# ET6801 register map
Vendor: ETMCU Inc.; File version: v0.0.1
CPU: CM7 r2p1, little endian, MPU, FPU, I-cache, D-cache, ITCM, DTCM, 4 interrupt priority bits
Registers are 32-bit, read-write, reset 0x0 unless marked. A register's access mark holds for its fields unless they carry their own. Offsets are from the block's base; [hi:lo] are bit positions; lines under a group give offsets from that group; {n}, {i} and the like mark numbered series.

## AHBDMA0 (part 1 of 2) — Provide an overview of the purpose and functionality of the peripheral: hdmac_cfg
Base 0x40200000
Same registers: AHBDMA1 0x40201000
{0x0+0x58*i} CHANNELX_CONFIG_CH{i} group (i=0..7)
  0x00 SARX
    [31:0] SAR — Current Source Address of DMA transfer. Updated after each source transfer. The SINC field in the CTLx register determines whether the address increments, decrements, or is left unchanged on every source transfer through the block transfer.Exists: AlwaysVolatile: true
  0x08 DARX
    [31:0] DAR — Current Destination address of DMA transfer. Updated after each destination transfer. The DINC field in the CTLx register determines whether the address increments, decrements, or is left unchanged on every destination transfer throughout the block transfer.
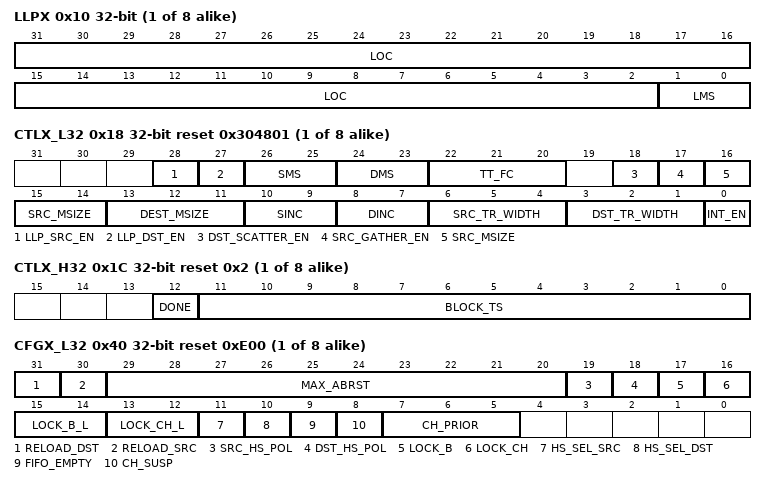
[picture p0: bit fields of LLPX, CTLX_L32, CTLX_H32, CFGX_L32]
  0x10 LLPX
    [31:2] LOC — Starting Address In Memory of next LLI if block chaining is enabled. Note that the two LSBs of the starting address are not stored because the address is assumed to be aligned to a 32-bit boundary. LLI accesses are always 32-bit accesses (Hsize=2) aligned to 32-bit boundaries and cannot be changed or programmed to anything other than 32-bit.
    [1:0] LMS — List Master Select. Identifies the AHB layer/interface where the memory device that stores the next linked list item resides. Values: 0x0 (LIST_MASTER_SELECT_1): The memory device stores the next linked list item on AHB master 1
  0x18 CTLX_L32 reset 0x304801 (reset mask 0xFFFFEFF8)
    [28] LLP_SRC_EN — Block chaining is enabled on the source side only if the LLP_SRC_EN field is high and LLPx.LOC is non-zero. For more information, see "Block Chaining using Linked Lists".Values: 0x0 (LLP_SRC_DISABLE): Block chaining using Linked List is disabled on the Source side0x1 (LLP_SRC_ENABLE): Block chaining using Linked List is enabled on the Source side
    [27] LLP_DST_EN — Block chaining is enabled on the destination side only if LLP_DST_EN field is high and LLPx.LOC is non-zero. For more information, see "Block Chaining using Linked Lists".Values: 0x0 (LLP_DST_DISABLE): Block chaining using Linked List is disabled on the Destination side0x1 (LLP_DST_ENABLE): Block chaining using Linked List is enabled on the Destination side
    [26:25] SMS — Source Master Select. Identifies the Master Interface layer where the source device (peripheral or memory) resides. Values: 0x0 (SMS_0): Source device (peripheral or memory) is accessed from AHB master 1
    [24:23] DMS — Destination Master Select. Identifies the Master Interface layer where the destination device (peripheral or memory) resides. Values: 0x0 (DMS_0): Destination device (peripheral or memory) is accessed from AHB master 1
    [22:20] TT_FC — Transfer Type and Flow Control.Values: 0x0 (TT_FC_0): Transfer type is Memory to Memory and Flow Controller is AHB DMAC0x1 (TT_FC_1): Transfer type is Memory to Peripheral and Flow Controller is AHB DMAC0x2 (TT_FC_2): Transfer type is Peripheral to Memory and Flow Controller is AHB DMAC0x3 (TT_FC_3): Transfer type is Peripheral to Peripheral and Flow Controller is AHB DMAC
    [18] DST_SCATTER_EN — Destination scatter enable. Scatter on the destination side is applicable only when the CTLx.DINC bit indicates an incrementing or decrementing address control.Values: 0x0 (DST_SCATTER_DISABLE): Destination Scatter is disabled0x1 (DST_SCATTER_ENABLE): Destination Scatter is enabled
    [17] SRC_GATHER_EN — Source gather enable. Gather on the source side is applicable only when the CTLx.SINC bit indicates an incrementing or decrementing address control.Values: 0x0 (SRC_GATHER_DISABLE): Source gather is disabled0x1 (SRC_GATHER_ENABLE): Source gather is enabled
    [16:14] SRC_MSIZE — Source Burst Transaction Length. Values: 0x0 (SRC_MSIZE_0): Number of data items to be transferred is 10x1 (SRC_MSIZE_1): Number of data items to be transferred is 40x2 (SRC_MSIZE_2): Number of data items to be transferred is 80x3 (SRC_MSIZE_3): Number of data items to be transferred is 160x4 (SRC_MSIZE_4): Number of data items to be transferred is 320x5 (SRC_MSIZE_5): Number of data items to be transferred is 640x6 (SRC_MSIZE_6): Number of data items to be transferred is 1280x7 (SRC_MSIZE_7): Number of data items to be transferred is 256
    [13:11] DEST_MSIZE — Destination Burst Transaction Length. NOTE: This value is not related to the AHB bus master HBURST bus.Values: 0x0 (DEST_MSIZE_0): Number of data items to be transferred is 10x1 (DEST_MSIZE_1): Number of data items to be transferred is 40x2 (DEST_MSIZE_2): Number of data items to be transferred is 80x3 (DEST_MSIZE_3): Number of data items to be transferred is 160x4 (DEST_MSIZE_4): Number of data items to be transferred is 320x5 (DEST_MSIZE_5): Number of data items to be transferred is 640x6 (DEST_MSIZE_6): Number of data items to be transferred is 1280x7 (DEST_MSIZE_7): Number of data items to be transferred is 256
    [10:9] SINC — Source Address Increment. Indicates whether to increment or decrement the source address on every source transfer. If the device is fetching data from a source peripheral FIFO with a fixed address, then set this field to "No change".Values: 0x0 (SINC_0): Increments the source address0x1 (SINC_1): Decrements the source address0x2 (SINC_2): No change in the source address0x3 (SINC_3): No change in the source address
    [8:7] DINC — Destination Address Increment. Indicates whether to increment or decrement the destination address on every destination transfer. If your device is writing data to a destination peripheral FIFO with a fixed address, then set this field to \"No Change\".Values: 0x0 (DINC_0): Increments the destination address0x1 (DINC_1): Decrements the destination address0x2 (DINC_2): No change in the destination address0x3 (DINC_3): No change in the destination address
    [6:4] SRC_TR_WIDTH — Source Transfer Width. Mapped to AHB bus hsize. Values: 0x0 (SRC_TR_WIDTH_0): Source transfer width is 8 bits0x1 (SRC_TR_WIDTH_1): Source transfer width is 16 bits0x2 (SRC_TR_WIDTH_2): Source transfer width is 32 bits0x3 (SRC_TR_WIDTH_3): Source transfer width is 64 bits0x4 (SRC_TR_WIDTH_4): Source transfer width is 128 bits0x5 (SRC_TR_WIDTH_5): Source transfer width is 256 bits0x6 (SRC_TR_WIDTH_6): Source transfer width is 256 bits0x7 (SRC_TR_WIDTH_7): Source transfer width is 256 bits
    [3:1] DST_TR_WIDTH — Destination Transfer Width. Mapped to AHB bus hsize. Values: 0x0 (DST_TR_WIDTH_0): Destination transfer width is 8 bits0x1 (DST_TR_WIDTH_1): Destination transfer width is 16 bits0x2 (DST_TR_WIDTH_2): Destination transfer width is 32 bits0x3 (DST_TR_WIDTH_3): Destination transfer width is 64 bits0x4 (DST_TR_WIDTH_4): Destination transfer width is 128 bits0x5 (DST_TR_WIDTH_5): Destination transfer width is 256 bits0x6 (DST_TR_WIDTH_6): Destination transfer width is 256 bits0x7 (DST_TR_WIDTH_7): Destination transfer width is 256 bits
    [0] INT_EN — Interrupt Enable Bit. If set, then all interrupt-generating sources are enabled. Functions as a global mask bit for all interrupts for the channel; raw* interrupt registers still assert if CTLx.INT_EN=0.Values: 0x0 (INTERRUPT_DISABLE): Interrupt is disabled0x1 (INTERRUPT_ENABLE): Interrupt is enabled
  0x1C CTLX_H32 reset 0x2 (reset mask 0xFFF80000)
    [12] DONE — Done bit.Values: 0x0 (DISABLED): DONE bit is deasserted at the end of block transfer0x1 (ENABLED): SET the DONE bit at the end of block transfer
    [11:0] BLOCK_TS — Block Transfer Size.
  0x20 SSTATX
    [31:0] SSTAT — Source status information retrieved by hardware from the address pointed to by the contents of the STATARx register
  0x28 DSTATX
    [31:0] DSTAT — Destination status information retrieved by hardware from the address pointed to by the contents of DSTATARx register.
  0x30 SSTATARX
    [31:0] SSTATAR — Pointer from where hardware can fetch the source status information, which is registered in the SSTATx register and written out to the SSTATx register location of the LLI before the start of the next block.
  0x38 DSTATARX
    [31:0] DSTATAR — Pointer from where hardware can fetch the destination status information, which is registered in the DSTATx register and written out to the DSTATx register location of the LLI before the start of the next block.
  0x40 CFGX_L32 reset 0xE00 (reset mask 0x7FFFFFF)
    [31] RELOAD_DST — Automatic Destination Reload. Values: 0x0 (DISABLE): Destination Reload Disabled.0x1 (ENABLE): Destination Reload Enabled
    [30] RELOAD_SRC — Automatic Source Reload. Values: 0x0 (DISABLE): Source Reload Disabled0x1 (ENABLE): Source Reload Enabled
    [29:20] MAX_ABRST — Maximum AMBA Burst Length.
    [19] SRC_HS_POL — Source Handshaking Interface Polarity.Values: 0x0 (ACTIVE_HIGH): Source Handshaking Interface Polarity is Active high0x1 (ACTIVE_LOW): Source Handshaking Interface Polarity is Active low
    [18] DST_HS_POL — Destination Handshaking Interface Polarity.Values: 0x0 (ACTIVE_HIGH): Destination Handshaking Interface Polarity is Active high0x1 (ACTIVE_LOW): Destination Handshaking Interface Polarity is Active low
    [17] LOCK_B — Bus Lock Bit. When active, the AHB bus master signal hlock is asserted for the duration specified in CFGx.LOCK_B_L. Values: 0x0 (DISABLED): Bus lock bit is not enabled0x1 (ENABLED): Bus lock bit is enabledExists: DMAH_CHx_LOCK_EN
    [16] LOCK_CH — Channel Lock Bit. When the channel is granted control of the master bus interface and if the CFGx.LOCK_CH bit is asserted, then no other channels are granted control of the master bus interface for the duration specified in CFGx.LOCK_CH_L.Values: 0x0 (DISABLED): Channel lock bit is not enabled0x1 (ENABLED): Channel lock bit is enabled
    [15:14] LOCK_B_L — Bus lock level. Indicates the duration over which CFGx.LOCK_B bit applies. Values: 0x0 (LOCK_B_L_0): Over complete DMA transfer0x1 (LOCK_B_L_1): Over complete DMA block transfer0x2 (LOCK_B_L_2): Over complete DMA transaction0x3 (LOCK_B_L_3): Over complete DMA transaction
    [13:12] LOCK_CH_L — Channel Local Level. Indicates the duration over which CFGx.LOCK_CH applies. Values: 0x0 (LOCK_CH_L_0): Over complete DMA transfer0x1 (LOCK_CH_L_1): Over complete DMA block transfer0x2 (LOCK_CH_L_2): Over complete DMA transaction0x3 (LOCK_CH_L_3): Over complete DMA transaction
    [11] HS_SEL_SRC — Source Software or Hardware Handshaking Select. This register selects which of the handshaking interfaces - hardware or software - is active for source requests on this channel. If the source peripheral is memory, then this bit is ignored.Values: 0x0 (HARDWARE_HS): Hardware handshaking interface. Software initiated transaction requests are ignored.0x1 (SOFTWARE_HS): Software handshaking interface. Hardware initiated transaction requests are ignored.
    [10] HS_SEL_DST — Destination Software or Hardware Handshaking Select. This register selects which of the handshaking interfaces - hardware or software - is active for destination requests on this channel. If the destination peripheral is memory, then this bit is ignored.Values: 0x0 (HARDWARE_HS): Hardware handshaking interface. Software initiated transaction requests are ignored.0x1 (SOFTWARE_HS): Software handshaking interface. Hardware initiated transaction requests are ignored.
    [9] FIFO_EMPTY ro — Channel FIFO status. Indicates if there is data left in the channel FIFO. Can be used in conjunction with CFGx.CH_SUSP to cleanly disable a channel. For more information, refer to "Disabling a Channel Prior to Transfer Completion".Values: 0x0 (NOT_EMPTY): Channel FIFO is not empty0x1 (EMPTY): Channel FIFO is empty
    [8] CH_SUSP — Channel Suspend. Suspends all DMA data transfers from the source until this bit is cleared. There is no guarantee that the current transaction will complete. Can also be used in conjunction with CFGx.FIFO_EMPTY to cleanly disable a channel without losing any data.0x0 (NOT_SUSPENDED): DMA transfer from the source is not suspended0x1 (SUSPENDED): Suspend DMA transfer from the source
    [7:5] CH_PRIOR — Channel Priority. A priority of 7 is the highest priority, and 0 is the lowest. This field must be programmed within the range 0 to DMAH_NUM_CHANNELS-1. A programmed value outside this range will cause erroneous behavior.DMA CH0默认值为0，DMA CH1 默认值为1，依次类推，DMA CH7 默认值为7Values: 0x0 (CH_PRIOR_0): Channel priority is 00x1 (CH_PRIOR_1): Channel priority is 10x2 (CH_PRIOR_2): Channel priority is 20x3 (CH_PRIOR_3): Channel priority is 30x4 (CH_PRIOR_4): Channel priority is 40x5 (CH_PRIOR_5): Channel priority is 50x6 (CH_PRIOR_6): Channel priority is 60x7 (CH_PRIOR_7): Channel priority is 7
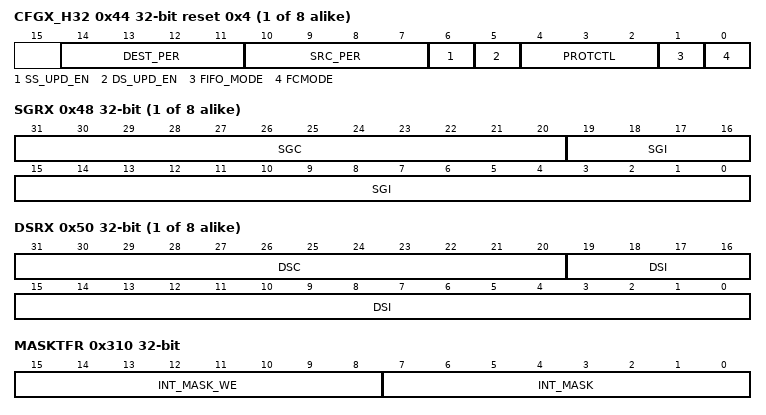
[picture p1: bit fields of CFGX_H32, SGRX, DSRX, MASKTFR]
  0x44 CFGX_H32 reset 0x4 (reset mask 0xFFFE0000)
    [14:11] DEST_PER — Destination hardware interface.Assigns a hardware handshaking interface (0 : 15) to the source of channel xThe channel can then communicate with the destination peripheral connected to that interface through the assigned hardware handshaking interface.
    [10:7] SRC_PER — Source Hardware Interface..Assigns a hardware handshaking interface (0 : 15) to the source of channel x
    [6] SS_UPD_EN — Source Status Update Enable. Source status information is fetched only from the location pointed to by the SSTATARx register, stored in the SSTATx register and written out to the SSTATx location of the LLI, if SS_UPD_EN is high.Values: 0x0 (DISABLED): Source Status Update is disabled.0x1 (ENABLED): Source Status Update is enabled.
    [5] DS_UPD_EN — Destination Status Update Enable. Destination status information is fetched only from the location pointed to by the DSTATARx register, stored in the DSTATx register and written out to the DSTATx location of the LLI, if DS_UPD_EN is high.Values: 0x0 (DISABLED): Destination Status Update is disabled0x1 (ENABLED): Destination Status Update is enabled
    [4:2] PROTCTL — Protection Control bits used to drive the AHB HPROT[3:1] bus. The AMBA Specification recommends that the default of HPROT indicates a non-cached, non-buffered, privileged data access. The reset value is used to indicate such an access.HPROT[0] is tied high because all transfers are data accesses, as there are no opcode fetches.There is a one-to-one mapping of these register bits to the HPROT[3:1] master interface signals.Mapping of HPROT bus is as follows:1'b1 to HPROT[0]CFGx.PROTCTL[1] to HPROT[1]CFGx.PROTCTL[2] to HPROT[2]CFGx.PROTCTL[3] to HPROT[3]Values: 0x0 (PROT_0): Drive the AHB HPROT[0] bus.The AMBA Specification recommends that the default value of HPROT indicates a non-cached, non-buffered, privileged data access0x1 (PROT_1): Drive the AHB HPROT[1] bus.The AMBA Specification recommends that the default value of HPROT indicates a non-cached, non-buffered, privileged data access0x2 (PROT_2): Drive the AHB HPROT[2] bus.The AMBA Specification recommends that the default value of HPROT indicates a non-cached, non-buffered, privileged data access0x3 (PROT_3): Drive the AHB HPROT[3] bus.The AMBA Specification recommends that the default value of HPROT indicates a non-cached, non-buffered, privileged data access0x4 (PROT_4): Drive the AHB HPROT[4] bus.The AMBA Specification recommends that the default value of HPROT indicates a non-cached, non-buffered, privileged data access0x5 (PROT_5): Drive the AHB HPROT[5] bus.The AMBA Specification recommends that the default value of HPROT indicates a non-cached, non-buffered, privileged data access0x5 (PROT_6): Drive the AHB HPROT[6] bus.The AMBA Specification recommends that the default value of HPROT indicates a non-cached, non-buffered, privileged data access0x7 (PROT_7): Drive the AHB HPROT[7] bus.The AMBA Specification recommends that the default value of HPROT indicates a non-cached, non-buffered, privileged data access
    [1] FIFO_MODE — FIFO Mode Select. Determines how much space or data needs to be available in the FIFO before a burst transaction request is serviced.Values: 0x0 (FIFO_MODE_0): Space/data available for single AHB transfer of the specified transfer width0x1 (FIFO_MODE_1): Data available is greater than or equal to half the FIFO depth for destination transfers and space available is greater than half the fifo depth for source transfers. The exceptions are at the end of a burst transaction request or at the end of a block transfer.
    [0] FCMODE — Flow Control Mode. Determines when source transaction requests are serviced when the Destination Peripheral is the flow controller.Values: 0x0 (FCMODE_0): Source transaction requests are serviced when they occur. Data pre-fetching is enabled0x1 (FCMODE_1): Source transaction requests are not serviced until a destination transaction request occurs. In this mode, the amount of data transferred from the source is limited so that it is guaranteed to be transferred to the destination prior to block termination by the destination. Data pre-fetching is disabled.
  0x48 SGRX
    [31:20] SGC — Source Gather Count. Source contiguous transfer count between successive gather boundaries.
    [19:0] SGI — Source Gather Interval.
  0x50 DSRX
    [31:20] DSC — Destination Scatter Count. Destination contiguous transfer count between successive scatter boundaries.
    [19:0] DSI — Destination Scatter Interval.
0x2C0 RAWTFR (reset mask 0xFF000000)
  [7:0] RAW — Raw Status for IntTfr InterruptValues: 0x0 (INACTIVE): Inactive Raw Interrupt Status0x1 (ACTIVE): Active Raw Interrupt Status
0x2C8 RAWBLOCK (reset mask 0xFF000000)
  [7:0] RAW — Raw Status for IntBlock InterruptValues: 0x0 (INACTIVE): Inactive Raw Interrupt Status0x1 (ACTIVE): Active Raw Interrupt Status
0x2D0 RAWSRCTRAN (reset mask 0xFF000000)
  [7:0] RAW — Raw Status for IntSrcTran InterruptValues: 0x0 (INACTIVE): Inactive Raw Interrupt Status0x1 (ACTIVE): Active Raw Interrupt Status
0x2D8 RAWDSTTRAN (reset mask 0xFF000000)
  [7:0] RAW — Raw Status for IntDstTran InterruptValues: 0x0 (INACTIVE): Inactive Raw Interrupt Status0x1 (ACTIVE): Active Raw Interrupt Status
0x2E0 RAWERR (reset mask 0xFF000000)
  [7:0] RAW — Raw Status for IntErr InterruptValues: 0x0 (INACTIVE): Inactive Raw Interrupt Status0x1 (ACTIVE): Active Raw Interrupt Status
0x2E8 STATUSTFR ro (reset mask 0xFF000000)
  [7:0] STATUS — Status for IntTfr InterruptValues: 0x0 (INACTIVE): Inactive Interrupt Status0x1 (ACTIVE): Active Interrupt Status
0x2F0 STATUSBLOCK ro (reset mask 0xFF000000)
  [7:0] STATUS — Status for IntBlock InterruptValues: 0x0 (INACTIVE): Inactive Interrupt Status0x1 (ACTIVE): Active Interrupt Status
0x2F8 STATUSSRCTRAN ro (reset mask 0xFF000000)
  [7:0] STATUS — Status for IntSrcTran InterruptValues: 0x0 (INACTIVE): Inactive Interrupt Status0x1 (ACTIVE): Active Interrupt Status
0x300 STATUSDSTTRAN ro (reset mask 0xFF000000)
  [7:0] STATUS — Status for IntDstTran InterruptValues: 0x0 (INACTIVE): Inactive Interrupt Status0x1 (ACTIVE): Active Interrupt Status
0x308 STATUSERR ro (reset mask 0xFF000000)
  [7:0] STATUS — Status for IntErr InterruptValues: 0x0 (INACTIVE): Inactive Interrupt Status0x1 (ACTIVE): Active Interrupt Status
0x310 MASKTFR (reset mask 0xFFFF0000)
  [15:8] INT_MASK_WE — Interrupt Mask Write EnableValues: 0x0 (DISABLED): Interrupt mask write disable0x1 (ENABLED): Interrupt mask write enable
  [7:0] INT_MASK — Mask for IntTfr InterruptValues: 0x0 (MASK): Mask the interrupts0x1 (UNMASK): Unmask the interrupts
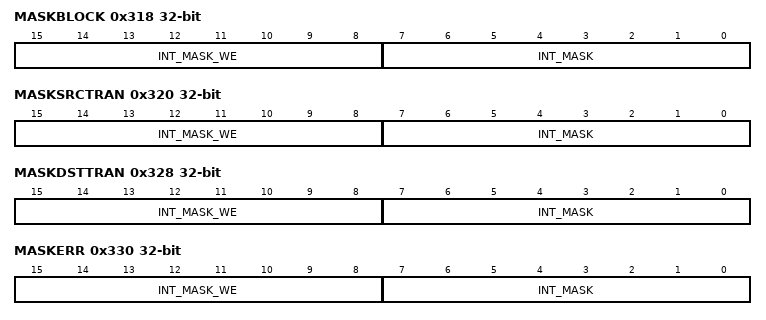
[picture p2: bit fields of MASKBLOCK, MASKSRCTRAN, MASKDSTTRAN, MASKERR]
0x318 MASKBLOCK (reset mask 0xFFFF0000)
  [15:8] INT_MASK_WE — Interrupt Mask Write EnableValues: 0x0 (DISABLED): Interrupt mask write disable0x1 (ENABLED): Interrupt mask write enable
  [7:0] INT_MASK — Mask for IntBlock InterruptValues: 0x0 (MASK): Mask the interrupts0x1 (UNMASK): Unmask the interrupts
0x320 MASKSRCTRAN (reset mask 0xFFFF0000)
  [15:8] INT_MASK_WE — Interrupt Mask Write EnableValues: 0x0 (DISABLED): Interrupt mask write disable0x1 (ENABLED): Interrupt mask write enable
  [7:0] INT_MASK — Mask for IntSrcTran InterruptValues: 0x0 (MASK): Mask the interrupts0x1 (UNMASK): Unmask the interrupts
0x328 MASKDSTTRAN (reset mask 0xFFFF0000)
  [15:8] INT_MASK_WE — Interrupt Mask Write EnableValues: 0x0 (DISABLED): Interrupt mask write disable0x1 (ENABLED): Interrupt mask write enable
  [7:0] INT_MASK — Mask for IntDstTran InterruptValues: 0x0 (MASK): Mask the interrupts0x1 (UNMASK): Unmask the interrupts
0x330 MASKERR (reset mask 0xFFFF0000)
  [15:8] INT_MASK_WE — Interrupt Mask Write EnableValues: 0x0 (DISABLED): Interrupt mask write disable0x1 (ENABLED): Interrupt mask write enable
  [7:0] INT_MASK — Mask for IntErr InterruptValues: 0x0 (MASK): Mask the interrupts0x1 (UNMASK): Unmask the interrupts
0x338 CLEARTFR (reset mask 0xFF000000)
  [7:0] CLEAR — Clear for IntTfr InterruptValues: 0x0 (NOT_CLEAR): No effect0x1 (CLEAR): Clears interrupts
0x340 CLEARBLOCK (reset mask 0xFF000000)
  [7:0] CLEAR — Clear for IntBlock InterruptValues: 0x0 (NOT_CLEAR): No effect0x1 (CLEAR): Clears interrupts
0x348 CLEARSRCTRAN (reset mask 0xFF000000)
  [7:0] CLEAR — Clear for IntSrcTran InterruptValues: 0x0 (NOT_CLEAR): No effect0x1 (CLEAR): Clears interrupts
0x350 CLEARDSTTRAN (reset mask 0xFF000000)
  [7:0] CLEAR — Clear for IntDstTran InterruptValues: 0x0 (NOT_CLEAR): No effect0x1 (CLEAR): Clears interrupts
0x358 CLEARERR (reset mask 0xFF000000)
  [7:0] CLEAR — Clear for IntErr InterruptValues: 0x0 (NOT_CLEAR): No effect0x1 (CLEAR): Clears interrupts
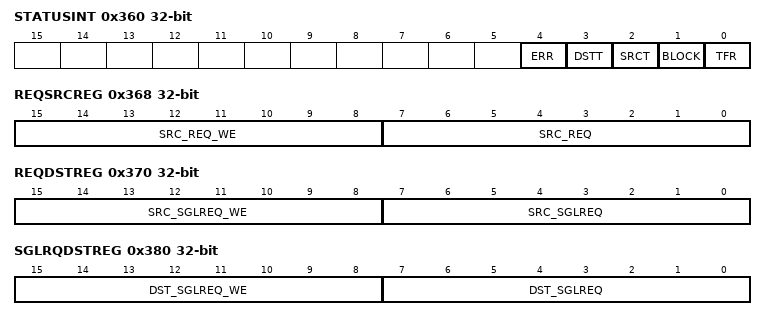
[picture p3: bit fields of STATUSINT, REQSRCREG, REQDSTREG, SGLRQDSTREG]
0x360 STATUSINT ro (reset mask 0xF8000000)
  [4] ERR — OR of the contents of StatusErrValues: 0x0 (INACTIVE): OR of the contents of StatusErr register is 00x1 (ACTIVE): OR of the contents of StatusErr register is 1
  [3] DSTT — OR of the contents of StatusDstTranValues: 0x0 (INACTIVE): OR of the contents of StatusDstTran register is 00x1 (ACTIVE): OR of the contents of StatusDstTran register is 1
  [2] SRCT — OR of the contents of StatusSrcTranValues: 0x0 (INACTIVE): OR of the contents of StatusSrcTran register is 00x1 (ACTIVE): OR of the contents of StatusSrcTran register is 1
  [1] BLOCK — OR of the contents of StatusBlock registerValues: 0x0 (INACTIVE): OR of the contents of StatusBlock register is 00x1 (ACTIVE): OR of the contents of StatusBlock register is 1
  [0] TFR — OR of the contents of StatusTfr registerValues: 0x0 (INACTIVE): OR of the contents of StatusTfr register is 00x1 (ACTIVE): OR of the contents of StatusTfr register is 1
0x368 REQSRCREG (reset mask 0xFFFF0000)
  [15:8] SRC_REQ_WE — Source Software Transaction Request write enableValues: 0x0 (DISABLED): Source request write Disable0x1 (ENABLED): Source request write Enable
  [7:0] SRC_REQ — Source Software Transaction RequestValues: 0x0 (INACTIVE): Source request is not active0x1 (ACTIVE): Source request is active
0x370 REQDSTREG (reset mask 0xFFFF0000)
  [15:8] SRC_SGLREQ_WE — Source Single Transaction Request write enableValues: 0x0 (DISABLED): Single write Disable0x1 (ENABLED): Single write Enable
  [7:0] SRC_SGLREQ — Source Single Transaction RequestValues: 0x0 (INACTIVE): Source request is not active0x1 (ACTIVE): Source request is active
0x380 SGLRQDSTREG (reset mask 0xFFFF0000)
  [15:8] DST_SGLREQ_WE — Destination Single Transaction Request write enableValues: 0x0 (DISABLED): Destination write Disable0x1 (ENABLED): Destination write Enable
  [7:0] DST_SGLREQ — Destination Single Transaction RequestValues: 0x0 (INACTIVE): Destination Single or burst request is not active0x1 (ACTIVE): Destination Single or burst request is active
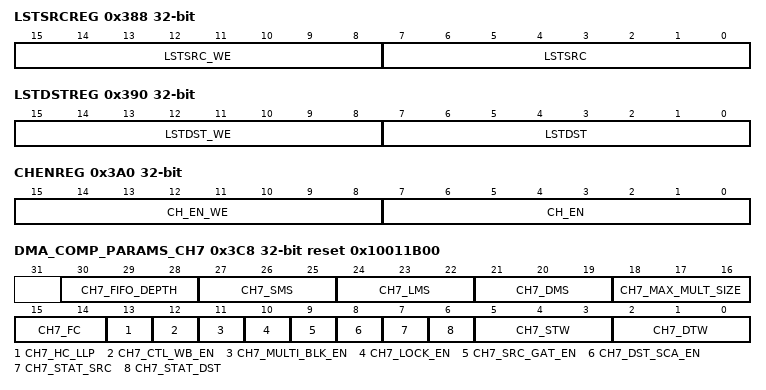
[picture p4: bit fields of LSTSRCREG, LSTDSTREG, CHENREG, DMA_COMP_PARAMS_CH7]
0x388 LSTSRCREG (reset mask 0xFFFF0000)
  [15:8] LSTSRC_WE — Source Last Transaction Request write enableValues: 0x0 (DISABLED): Source last transaction request write disable0x1 (ENABLED): Source last transaction request write enable
  [7:0] LSTSRC — Source Last Transaction Request registerValues: 0x0 (NOT_LAST): Not last transaction in current block0x1 (LAST): Last transaction in current block
0x390 LSTDSTREG (reset mask 0xFFFF0000)
  [15:8] LSTDST_WE — Source Last Transaction Request write enableValues: 0x0 (DISABLED): Destination last transaction request write disable0x1 (ENABLED): Destination last transaction request write enable
  [7:0] LSTDST — Destination Last Transaction RequestValues: 0x0 (NOT_LAST): Not last transaction in current block0x1 (LAST): Last transaction in current block
0x398 DMACFGREG (reset mask 0x80000000)
  [0] DMA_EN — AHB DMAC Enable bit.Values: 0x0 (DISABLED): AHB DMAC Disabled0x1 (ENABLED): AHB DMAC Enabled
0x3A0 CHENREG (reset mask 0xFFFF0000)
  [15:8] CH_EN_WE — Channel enable register write enable
  [7:0] CH_EN — Channel Enable. The ChEnReg.CH_EN bit is automatically cleared by hardware to disable the channel after the last AMBA transfer of the DMA transfer to the destination has completed. Software can therefore poll this bit to determine when this channel is free for a new DMA transfer.Values: 0x0 (DISABLED): Disable the channel0x1 (ENABLED): Enable the channel
0x3A8 DMAIDREG
  [31:0] DMA_ID — Hardcoded AHB DMAC peripheral ID.
0x3B0 DMATESTREG (reset mask 0x80000000)
  [0] TEST_SLV_IF — DMA Test registerValues: 0x0 (NORMAL_MODE): Puts the AHB slave interface into Normal mode0x1 (TEST_MODE): Puts the AHB slave interface into Test mode. In this mode, the readback value of the writable registers always matches the values written.
0x3B8 DMALPTIMEOUTREG reset 0x8 (reset mask 0xF0000000)
  [3:0] DMA_LP_TIMEOUT — This field holds timeout value of low power counter register.
0x3C8 DMA_COMP_PARAMS_CH7 ro reset 0x10011B00 (reset mask 0xFFFFFFFE)
  [30:28] CH7_FIFO_DEPTH — Values: 0x0 (FIFO_DEPTH_8): Channel 7 FIFO depth is 8 bytes 0x1 (FIFO_DEPTH_16): Channel 7 FIFO depth is 16 bytes 0x2 (FIFO_DEPTH_32): Channel 7 FIFO depth is 32 bytes 0x3 (FIFO_DEPTH_64): Channel 7 FIFO depth is 64 bytes 0x4 (FIFO_DEPTH_128): Channel 7 FIFO depth is 128 bytes 0x5 (FIFO_DEPTH_256): Channel 7 FIFO depth is 256 bytes
  [27:25] CH7_SMS — Values: 0x0 (MASTER_1): Hardcode the AHB master 1 interface attached to the source of channel 70x1 (MASTER_2): Hardcode the AHB master 2 interface attached to the source of channel 70x2 (MASTER_3): Hardcode the AHB master 3 interface attached to the source of channel 70x3 (MASTER_4): Hardcode the AHB master 4 interface attached to the source of channel 70x4 (PROGRAMMABLE): Programmable
  [24:22] CH7_LMS — Values: 0x0 (MASTER_1): Hardcode the AHB master 1 interface attached to the LLP peripherals of channel 70x1 (MASTER_2): Hardcode the AHB master 2 interface attached to the LLP peripherals of channel 70x2 (MASTER_3): Hardcode the AHB master 3 interface attached to the LLP peripherals of channel 70x3 (MASTER_4): Hardcode the AHB master 4 interface attached to the LLP peripherals of channel 70x4 (PROGRAMMABLE): Programmable
  [21:19] CH7_DMS — Values: 0x0 (MASTER_1): Hardcode the AHB master 1 interface attached to the channel 7 destination0x1 (MASTER_2): Hardcode the AHB master 2 interface attached to the channel 7 destination0x2 (MASTER_3): Hardcode the AHB master 3 interface attached to the channel 7 destination0x3 (MASTER_4): Hardcode the AHB master 4 interface attached to the channel 7 destination0x4 (PROGRAMMABLE): Programmable
  [18:16] CH7_MAX_MULT_SIZE — Values: 0x0 (MAX_MULT_SIZE_4): Maximum value of burst transaction size that can be programmed for channel 7 is 40x1 (MAX_MULT_SIZE_8): Maximum value of burst transaction size that can be programmed for channel 7 is 80x2 (MAX_MULT_SIZE_16): Maximum value of burst transaction size that can be programmed for channel 7 is 160x3 (MAX_MULT_SIZE_32): Maximum value of burst transaction size that can be programmed for channel 7 is 320x4 (MAX_MULT_SIZE_64): Maximum value of burst transaction size that can be programmed for channel 7 is 640x5 (MAX_MULT_SIZE_128): Maximum value of burst transaction size that can be programmed for channel 7 is 1280x6 (MAX_MULT_SIZE_256): Maximum value of burst transaction size that can be programmed for channel 7 is 2560x7 (RESERVED): Reserved
  [15:14] CH7_FC — Values: 0x0 (FC_DMA): Flow controller is DMA for channel 70x1 (FC_SRC): Flow controller is Source for channel 70x2 (FC_DST): Flow controller is Destination for channel 70x3 (FC_ANY): Flow controller is ANY for channel 7
  [13] CH7_HC_LLP — Values: 0x0 (PROGRAMMABLE): Exclude logic to hardcode Channel 7 LLP register to 00x0 (HARDCODED): Hardcode Channel 7 LLP register to 0
  [12] CH7_CTL_WB_EN — Values: 0x0 (FALSE): Exclude logic to enable control register writeback after each block transfer on channel 70x1 (TRUE): Include logic to enable control register writeback after each block transfer on channel 7
  [11] CH7_MULTI_BLK_EN — Values: 0x0 (FALSE): Exclude logic to enable channel multi-block DMA transfers on channel 70x1 (TRUE): Include logic to enable channel multi-block DMA transfers on channel 7
  [10] CH7_LOCK_EN — Values: 0x0 (FALSE): Exclude logic to enable channel or bus locking on channel 70x1 (TRUE): Include logic to enable channel or bus locking on channel 7
  [9] CH7_SRC_GAT_EN — Values: 0x0 (FALSE): Exclude logic to enable the gather feature on channel 70x1 (TRUE): Include logic to enable the gather feature on channel 7
  [8] CH7_DST_SCA_EN — Values: 0x0 (FALSE): Exclude logic to enable the scatter feature on channel 70x1 (TRUE): Include logic to enable the scatter feature on channel 7
  [7] CH7_STAT_SRC — Values: 0x0 (FALSE): Exclude logic to fetch a status register from source peripheral of channel 7 and write this status information to memory at end of each block transfer0x1 (TRUE): Include logic to fetch a status register from source peripheral of channel 7 and write this status information to memory at end of each block transfer
  [6] CH7_STAT_DST — Values: 0x0 (FALSE): Exclude logic to fetch a status register from destination peripheral of channel 7 and write this status information to memory at end of each block transfer0x1 (TRUE): Include logic to fetch a status register from destination peripheral of channel 7 and write this status information to memory at end of each block transfer
  [5:3] CH7_STW — Values: 0x0 (NO_HARDCODE): No hardcode0x1 (STW_8): Hardcode the channel 7's source transfer width to 8 bits0x2 (STW_16): Hardcode the channel 7's source transfer width to 16 bits0x3 (STW_32): Hardcode the channel 7's source transfer width to 32 bits0x4 (STW_64): Hardcode the channel 7's source transfer width to 64 bits0x5 (STW_128): Hardcode the channel 7's source transfer width to 128 bits0x6 (STW_256): Hardcode the channel 7's source transfer width to 256 bits0x7 (RESERVED): Reserved
  [2:0] CH7_DTW — Values: 0x0 (NO_HARDCODE): NO Hardcode0x1 (DTW_8): Hardcode the channel 7's destination transfer width to 8 bits0x2 (DTW_16): Hardcode the channel 7's destination transfer width to 16 bits0x3 (DTW_32): Hardcode the channel 7's destination transfer width to 32 bits0x4 (DTW_64): Hardcode the channel 7's destination transfer width to 64 bits0x5 (DTW_128): Hardcode the channel 7's destination transfer width to 128 bits0x6 (DTW_256): Hardcode the channel 7's destination transfer width to 256 bits0x7 (RESERVED): Reserved
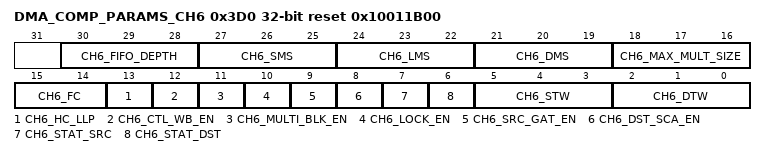
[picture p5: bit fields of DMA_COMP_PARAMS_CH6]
0x3D0 DMA_COMP_PARAMS_CH6 ro reset 0x10011B00 (reset mask 0xFFFFFFFE)
  [30:28] CH6_FIFO_DEPTH — Values: 0x0 (IFO_DEPTH_8): Channel 6 FIFO depth is 8 bytes 0x1 (FIFO_DEPTH_16): Channel 6 FIFO depth is 16 bytes 0x2 (FIFO_DEPTH_32): Channel 6 FIFO depth is 32 bytes 0x3 (FIFO_DEPTH_64): Channel 6 FIFO depth is 64 bytes 0x4 (FIFO_DEPTH_128): Channel 6 FIFO depth is 128 bytes 0x5 (FIFO_DEPTH_256): Channel 6 FIFO depth is 256 bytes
  [27:25] CH6_SMS — Values: 0x0 (MASTER_1): Hardcode the AHB master 1 interface attached to the source of channel 60x1 (MASTER_2): Hardcode the AHB master 2 interface attached to the source of channel 60x2 (MASTER_3): Hardcode the AHB master 3 interface attached to the source of channel 60x3 (MASTER_4): Hardcode the AHB master 4 interface attached to the source of channel 60x4 (PROGRAMMABLE): Programmable
  [24:22] CH6_LMS — Values: 0x0 (MASTER_1): Hardcode the AHB master 1 interface attached to the LLP peripherals of channel 60x1 (MASTER_2): Hardcode the AHB master 2 interface attached to the LLP peripherals of channel 60x2 (MASTER_3): Hardcode the AHB master 3 interface attached to the LLP peripherals of channel 60x3 (MASTER_4): Hardcode the AHB master 4 interface attached to the LLP peripherals of channel 60x4 (PROGRAMMABLE): Programmable
  [21:19] CH6_DMS — Values: 0x0 (MASTER_1): Hardcode the AHB master 1 interface attached to the channel 6 destination0x1 (MASTER_2): Hardcode the AHB master 2 interface attached to the channel 6 destination0x2 (MASTER_3): Hardcode the AHB master 3 interface attached to the channel 6 destination0x3 (MASTER_4): Hardcode the AHB master 4 interface attached to the channel 6 destination0x4 (PROGRAMMABLE): Programmable
  [18:16] CH6_MAX_MULT_SIZE — Values: 0x0 (MAX_MULT_SIZE_4): Maximum value of burst transaction size that can be programmed for channel 6 is 40x1 (MAX_MULT_SIZE_8): Maximum value of burst transaction size that can be programmed for channel 6 is 80x2 (MAX_MULT_SIZE_16): Maximum value of burst transaction size that can be programmed for channel 6 is 160x3 (MAX_MULT_SIZE_32): Maximum value of burst transaction size that can be programmed for channel 6 is 320x4 (MAX_MULT_SIZE_64): Maximum value of burst transaction size that can be programmed for channel 6 is 640x5 (MAX_MULT_SIZE_128): Maximum value of burst transaction size that can be programmed for channel 6 is 1280x6 (MAX_MULT_SIZE_256): Maximum value of burst transaction size that can be programmed for channel 6 is 2560x7 (RESERVED): Reserved
  [15:14] CH6_FC — Values: 0x0 (FC_DMA): Flow controller is DMA for channel 60x1 (FC_SRC): Flow controller is Source for channel 60x2 (FC_DST): Flow controller is Destination for channel 70x3 (FC_ANY): Flow controller is ANY for channel 6
  [13] CH6_HC_LLP — Values: 0x0 (PROGRAMMABLE): Exclude logic to hardcode Channel 6 LLP register to 00x0 (HARDCODED): Hardcode Channel 6 LLP register to 0
  [12] CH6_CTL_WB_EN — Values: 0x0 (FALSE): Exclude logic to enable control register writeback after each block transfer on channel 60x1 (TRUE): Include logic to enable control register writeback after each block transfer on channel 6
  [11] CH6_MULTI_BLK_EN — Values: 0x0 (FALSE): Exclude logic to enable channel multi-block DMA transfers on channel 60x1 (TRUE): Include logic to enable channel multi-block DMA transfers on channel 6
  [10] CH6_LOCK_EN — Values: 0x0 (FALSE): Exclude logic to enable channel or bus locking on channel 60x1 (TRUE): Include logic to enable channel or bus locking on channel 6
  [9] CH6_SRC_GAT_EN — Values: 0x0 (FALSE): Exclude logic to enable the gather feature on channel 60x1 (TRUE): Include logic to enable the gather feature on channel 6
  [8] CH6_DST_SCA_EN — Values: 0x0 (FALSE): Exclude logic to enable the scatter feature on channel 60x1 (TRUE): Include logic to enable the scatter feature on channel 6
  [7] CH6_STAT_SRC — Values: 0x0 (FALSE): Exclude logic to fetch a status register from source peripheral of channel 6 and write this status information to memory at end of each block transfer0x1 (TRUE): Include logic to fetch a status register from source peripheral of channel 6 and write this status information to memory at end of each block transfer
  [6] CH6_STAT_DST — Values: 0x0 (FALSE): Exclude logic to fetch a status register from destination peripheral of channel 6 and write this status information to memory at end of each block transfer0x1 (TRUE): Include logic to fetch a status register from destination peripheral of channel 6 and write this status information to memory at end of each block transfer
  [5:3] CH6_STW — Values: 0x0 (NO_HARDCODE): No hardcode0x1 (STW_8): Hardcode the channel 6's source transfer width to 8 bits0x2 (STW_16): Hardcode the channel 6's source transfer width to 16 bits0x3 (STW_32): Hardcode the channel 6's source transfer width to 32 bits0x4 (STW_64): Hardcode the channel 6's source transfer width to 64 bits0x5 (STW_128): Hardcode the channel 6's source transfer width to 128 bits0x6 (STW_256): Hardcode the channel 6's source transfer width to 256 bits0x7 (RESERVED): Reserved
  [2:0] CH6_DTW — Values: 0x0 (NO_HARDCODE): NO Hardcode0x1 (DTW_8): Hardcode the channel 6's destination transfer width to 8 bits0x2 (DTW_16): Hardcode the channel 6's destination transfer width to 16 bits0x3 (DTW_32): Hardcode the channel 6's destination transfer width to 32 bits0x4 (DTW_64): Hardcode the channel 6's destination transfer width to 64 bits0x5 (DTW_128): Hardcode the channel 6's destination transfer width to 128 bits0x6 (DTW_256): Hardcode the channel 6's destination transfer width to 256 bits0x7 (RESERVED): Reserved
